# CY8C4245AXI_483 register map
File version: 0.1
PSoC 4200
Registers are 8-bit, read-write, no defined reset value unless marked. A register's access mark holds for its fields unless they carry their own. Offsets are from the block's base; lines under a group give offsets from that group; [hi:lo] are bit positions; {n}, {i} and the like mark numbered series; 'fields as' and 'values as' point back to an identical list; <NAME> marks a mode.

## Memory map
0x00000000 Bank_Reg_1
0x00000000 AL_reg
0x00000000 AH_reg
0x00000000 STATE

## Bank_Reg_1
Base 0x00000000
0x400F0063 Bank_Reg_1_STATUS_REG
0x400F0083 Bank_Reg_1_MASK_REG
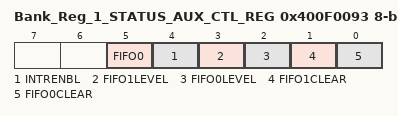
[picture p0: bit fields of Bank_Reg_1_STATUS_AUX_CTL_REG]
0x400F0093 Bank_Reg_1_STATUS_AUX_CTL_REG
  [5] FIFO0 — FIFO0 clear
    1=ENABLED (Enable counter); 0=DISABLED (Disable counter)
  [4] INTRENBL — Enables or disables the Interrupt
    1=ENABLED (Interrupt enabled); 0=DISABLED (Interrupt disabled)
  [3] FIFO1LEVEL — FIFO level
    1=ENABLED (FIFO LVL: input mode: FIFO at least 1/2 empty; output mode: FIFO at least 1/2 full); 0=DISABLED (FIFO LVL: input mode: FIFO not full; output mode: FIFO not empty)
  [2] FIFO0LEVEL — FIFO level
    values as FIFO1LEVEL
  [1] FIFO1CLEAR — FIFO clear
    1=ENABLED (Clear FIFO state); 0=DISABLED (Normal FIFO operation)
  [0] FIFO0CLEAR — FIFO clear
    values as FIFO1CLEAR

## AL_reg
Base 0x00000000
0x400F0062 AL_reg_STATUS_REG
0x400F0082 AL_reg_MASK_REG
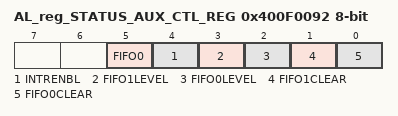
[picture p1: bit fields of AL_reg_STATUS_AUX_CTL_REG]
0x400F0092 AL_reg_STATUS_AUX_CTL_REG
  fields as Bank_Reg_1.Bank_Reg_1_STATUS_AUX_CTL_REG

## AH_reg
Base 0x00000000
0x400F0061 AH_reg_STATUS_REG
0x400F0081 AH_reg_MASK_REG
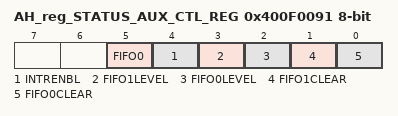
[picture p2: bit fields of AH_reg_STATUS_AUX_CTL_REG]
0x400F0091 AH_reg_STATUS_AUX_CTL_REG
  fields as Bank_Reg_1.Bank_Reg_1_STATUS_AUX_CTL_REG

## STATE
Base 0x00000000
0x400F0060 STATE_STATUS_REG
0x400F0080 STATE_MASK_REG
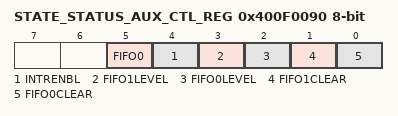
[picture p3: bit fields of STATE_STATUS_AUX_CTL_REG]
0x400F0090 STATE_STATUS_AUX_CTL_REG
  fields as Bank_Reg_1.Bank_Reg_1_STATUS_AUX_CTL_REG
